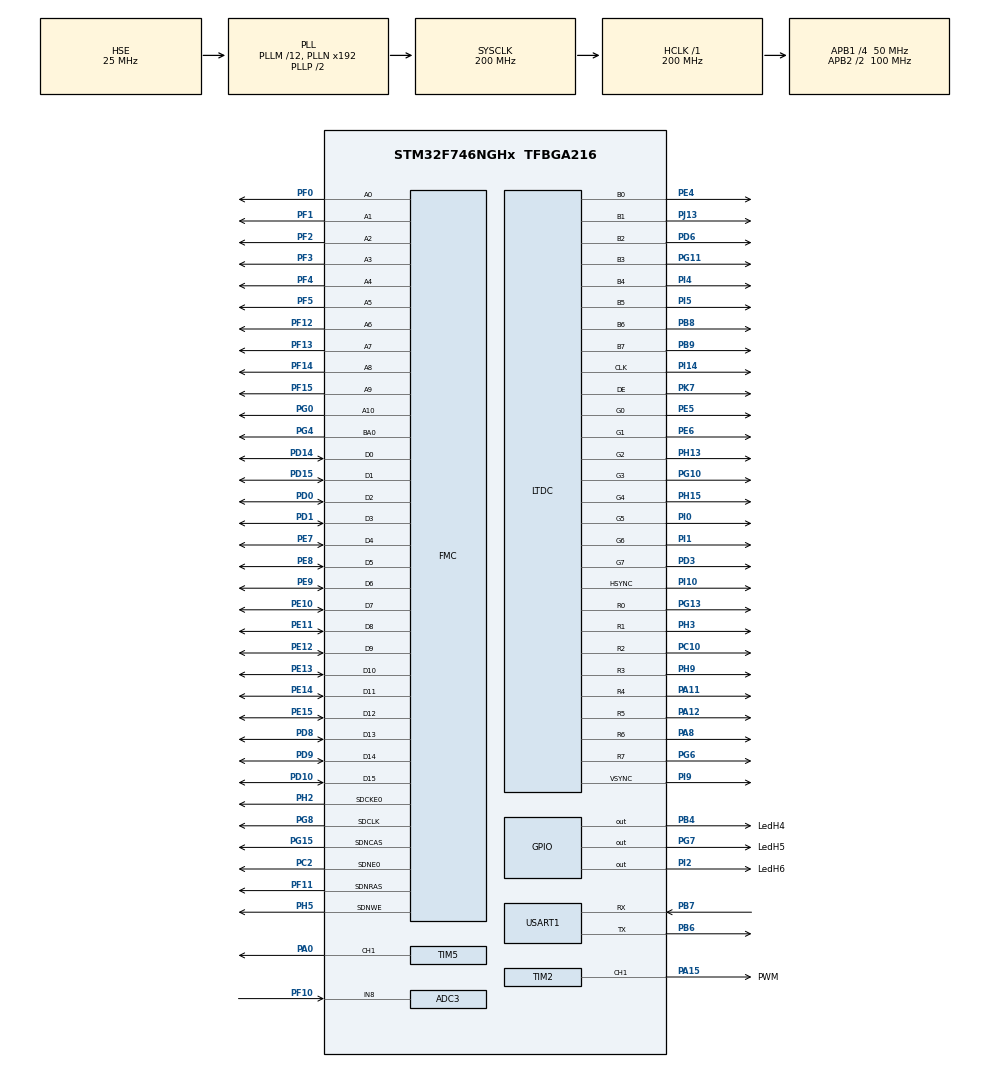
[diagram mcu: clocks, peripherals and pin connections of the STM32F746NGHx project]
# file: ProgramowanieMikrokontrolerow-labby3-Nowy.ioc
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ADC3.Channel-0\#ChannelRegularConversion=ADC_CHANNEL_8
ADC3.ContinuousConvMode=ENABLE
ADC3.NbrOfConversionFlag=1
ADC3.Rank-0\#ChannelRegularConversion=1
ADC3.SamplingTime-0\#ChannelRegularConversion=ADC_SAMPLETIME_3CYCLES
Dma.ADC3.0.Direction=DMA_PERIPH_TO_MEMORY
Dma.ADC3.0.FIFOMode=DMA_FIFOMODE_DISABLE
Dma.ADC3.0.Instance=DMA2_Stream0
Dma.ADC3.0.MemDataAlignment=DMA_MDATAALIGN_HALFWORD
Dma.ADC3.0.MemInc=DMA_MINC_ENABLE
Dma.ADC3.0.Mode=DMA_CIRCULAR
Dma.ADC3.0.PeriphDataAlignment=DMA_PDATAALIGN_HALFWORD
Dma.ADC3.0.PeriphInc=DMA_PINC_DISABLE
Dma.ADC3.0.Priority=DMA_PRIORITY_LOW
Dma.Request0=ADC3
Mcu.Family=STM32F7
Mcu.Name=STM32F746NGHx
Mcu.Package=TFBGA216
NVIC.ADC_IRQn=true\:0\:0\:false\:false\:true\:true\:true\:true
NVIC.DMA2_Stream0_IRQn=true\:0\:0\:false\:false\:true\:false\:true\:true
NVIC.PriorityGroup=NVIC_PRIORITYGROUP_4
NVIC.TIM2_IRQn=true\:0\:0\:false\:false\:true\:true\:true\:true
NVIC.TIM5_IRQn=true\:0\:0\:false\:false\:true\:true\:true\:true
PA0/WKUP.Signal=S_TIM5_CH1
PA11.Mode=RGB888
PA11.Signal=LTDC_R4
PA12.Mode=RGB888
PA12.Signal=LTDC_R5
PA15.GPIO_Label=PWM
PA15.Signal=S_TIM2_CH1_ETR
PA8.Mode=RGB888
PA8.Signal=LTDC_R6
PB4.GPIO_Label=LedH4
PB4.GPIO_PuPd=GPIO_PULLDOWN
PB4.Signal=GPIO_Output
PB6.Mode=Asynchronous
PB6.Signal=USART1_TX
PB7.Mode=Asynchronous
PB7.Signal=USART1_RX
PB8.Mode=RGB888
PB8.Signal=LTDC_B6
PB9.Mode=RGB888
PB9.Signal=LTDC_B7
PC10.Mode=RGB888
PC10.Signal=LTDC_R2
PC14/OSC32_IN.Mode=LSE-External-Oscillator
PC14/OSC32_IN.Signal=RCC_OSC32_IN
PC15/OSC32_OUT.Mode=LSE-External-Oscillator
PC15/OSC32_OUT.Signal=RCC_OSC32_OUT
PC2.Mode=SdramChipSelect1_1
PC2.Signal=FMC_SDNE0
PD0.Signal=FMC_D2_DA2
PD1.Signal=FMC_D3_DA3
PD10.Signal=FMC_D15_DA15
PD14.Signal=FMC_D0_DA0
PD15.Signal=FMC_D1_DA1
PD3.Mode=RGB888
PD3.Signal=LTDC_G7
PD6.Mode=RGB888
PD6.Signal=LTDC_B2
PD8.Signal=FMC_D13_DA13
PD9.Signal=FMC_D14_DA14
PE10.Signal=FMC_D7_DA7
PE11.Signal=FMC_D8_DA8
PE12.Signal=FMC_D9_DA9
PE13.Signal=FMC_D10_DA10
PE14.Signal=FMC_D11_DA11
PE15.Signal=FMC_D12_DA12
PE4.Mode=RGB888
PE4.Signal=LTDC_B0
PE5.Mode=RGB888
PE5.Signal=LTDC_G0
PE6.Mode=RGB888
PE6.Signal=LTDC_G1
PE7.Signal=FMC_D4_DA4
PE8.Signal=FMC_D5_DA5
PE9.Signal=FMC_D6_DA6
PF0.Signal=FMC_A0
PF1.Signal=FMC_A1
PF10.Mode=IN8
PF10.Signal=ADC3_IN8
PF11.Signal=FMC_SDNRAS
PF12.Signal=FMC_A6
PF13.Signal=FMC_A7
PF14.Signal=FMC_A8
PF15.Signal=FMC_A9
PF2.Signal=FMC_A2
PF3.Signal=FMC_A3
PF4.Signal=FMC_A4
PF5.Signal=FMC_A5
PG0.Signal=FMC_A10
PG10.Mode=RGB888
PG10.Signal=LTDC_G3
PG11.Mode=RGB888
PG11.Signal=LTDC_B3
PG13.Mode=RGB888
PG13.Signal=LTDC_R0
PG15.Signal=FMC_SDNCAS
PG4.Signal=FMC_A14_BA0
PG6.Mode=RGB888
PG6.Signal=LTDC_R7
PG7.GPIO_Label=LedH5
PG7.GPIO_PuPd=GPIO_PULLDOWN
PG7.Signal=GPIO_Output
PG8.Signal=FMC_SDCLK
PH0/OSC_IN.Mode=HSE-External-Oscillator
PH0/OSC_IN.Signal=RCC_OSC_IN
PH1/OSC_OUT.Mode=HSE-External-Oscillator
PH1/OSC_OUT.Signal=RCC_OSC_OUT
PH13.Mode=RGB888
PH13.Signal=LTDC_G2
PH15.Mode=RGB888
PH15.Signal=LTDC_G4
PH2.Mode=SdramChipSelect1_1
PH2.Signal=FMC_SDCKE0
PH3.Mode=RGB888
PH3.Signal=LTDC_R1
PH5.Signal=FMC_SDNWE
PH9.Mode=RGB888
PH9.Signal=LTDC_R3
PI0.Mode=RGB888
PI0.Signal=LTDC_G5
PI1.Mode=RGB888
PI1.Signal=LTDC_G6
PI10.Mode=RGB888
PI10.Signal=LTDC_HSYNC
PI14.Mode=RGB888
PI14.Signal=LTDC_CLK
PI2.GPIO_Label=LedH6
PI2.GPIO_PuPd=GPIO_PULLDOWN
PI2.Signal=GPIO_Output
PI4.Mode=RGB888
PI4.Signal=LTDC_B4
PI5.Mode=RGB888
PI5.Signal=LTDC_B5
PI9.Mode=RGB888
PI9.Signal=LTDC_VSYNC
PJ13.Mode=RGB888
PJ13.Signal=LTDC_B1
PK7.Mode=RGB888
PK7.Signal=LTDC_DE
ProjectManager.HeapSize=0x200
ProjectManager.StackSize=0x400
ProjectManager.TargetToolchain=STM32CubeIDE
RCC.AHBFreq_Value=200000000
RCC.APB1CLKDivider=RCC_HCLK_DIV4
RCC.APB1Freq_Value=50000000
RCC.APB1TimFreq_Value=100000000
RCC.APB2CLKDivider=RCC_HCLK_DIV2
RCC.APB2Freq_Value=100000000
RCC.APB2TimFreq_Value=200000000
RCC.CortexFreq_Value=200000000
RCC.HCLKFreq_Value=200000000
RCC.HSE_VALUE=25000000
RCC.HSI_VALUE=16000000
RCC.PLLM=12
RCC.PLLSAIN=50
RCC.PLLSourceVirtual=RCC_PLLSOURCE_HSE
RCC.SYSCLKFreq_VALUE=200000000
RCC.SYSCLKSource=RCC_SYSCLKSOURCE_PLLCLK
RCC.USBFreq_Value=200000000
RCC.VCOOutputFreq_Value=400000000
SH.FMC_A0.0=FMC_A0,11b-sda1
SH.FMC_A1.0=FMC_A1,11b-sda1
SH.FMC_A10.0=FMC_A10,11b-sda1
SH.FMC_A14_BA0.0=FMC_BA0,TwoSdramBanks1
SH.FMC_A2.0=FMC_A2,11b-sda1
SH.FMC_A3.0=FMC_A3,11b-sda1
SH.FMC_A4.0=FMC_A4,11b-sda1
SH.FMC_A5.0=FMC_A5,11b-sda1
SH.FMC_A6.0=FMC_A6,11b-sda1
SH.FMC_A7.0=FMC_A7,11b-sda1
SH.FMC_A8.0=FMC_A8,11b-sda1
SH.FMC_A9.0=FMC_A9,11b-sda1
SH.FMC_D0_DA0.0=FMC_D0,sd-16b-d1
SH.FMC_D10_DA10.0=FMC_D10,sd-16b-d1
SH.FMC_D11_DA11.0=FMC_D11,sd-16b-d1
SH.FMC_D12_DA12.0=FMC_D12,sd-16b-d1
SH.FMC_D13_DA13.0=FMC_D13,sd-16b-d1
SH.FMC_D14_DA14.0=FMC_D14,sd-16b-d1
SH.FMC_D15_DA15.0=FMC_D15,sd-16b-d1
SH.FMC_D1_DA1.0=FMC_D1,sd-16b-d1
SH.FMC_D2_DA2.0=FMC_D2,sd-16b-d1
SH.FMC_D3_DA3.0=FMC_D3,sd-16b-d1
SH.FMC_D4_DA4.0=FMC_D4,sd-16b-d1
SH.FMC_D5_DA5.0=FMC_D5,sd-16b-d1
SH.FMC_D6_DA6.0=FMC_D6,sd-16b-d1
SH.FMC_D7_DA7.0=FMC_D7,sd-16b-d1
SH.FMC_D8_DA8.0=FMC_D8,sd-16b-d1
SH.FMC_D9_DA9.0=FMC_D9,sd-16b-d1
SH.FMC_SDCLK.0=FMC_SDCLK,11b-sda1
SH.FMC_SDNCAS.0=FMC_SDNCAS,11b-sda1
SH.FMC_SDNRAS.0=FMC_SDNRAS,11b-sda1
SH.FMC_SDNWE.0=FMC_SDNWE,11b-sda1
SH.S_TIM2_CH1_ETR.0=TIM2_CH1,PWM Generation1 CH1
SH.S_TIM5_CH1.0=TIM5_CH1,PWM Generation1 CH1
TIM2.AutoReloadPreload=TIM_AUTORELOAD_PRELOAD_ENABLE
TIM2.Channel-PWM\ Generation1\ CH1=TIM_CHANNEL_1
TIM2.CounterMode=TIM_COUNTERMODE_CENTERALIGNED1
TIM2.OC1Preload_PWM=DISABLE
TIM2.Period=1999
TIM2.Pulse-PWM\ Generation1\ CH1=1000
TIM5.AutoReloadPreload=TIM_AUTORELOAD_PRELOAD_ENABLE
TIM5.Channel-PWM\ Generation1\ CH1=TIM_CHANNEL_1
TIM5.CounterMode=TIM_COUNTERMODE_CENTERALIGNED1
TIM5.Period=1999
USART1.VirtualMode-Asynchronous=VM_ASYNC
VP_CRC_VS_CRC.Mode=CRC_Activate
VP_DMA2D_VS_DMA2D.Mode=DMA2D_Activate
VP_TIM2_VS_ClockSourceINT.Mode=Internal
VP_TIM5_VS_ClockSourceINT.Mode=Internal
board=custom

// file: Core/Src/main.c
/* USER CODE BEGIN Header */
/**
  ******************************************************************************
  * @file           : main.c
  * @brief          : Main program body
  ******************************************************************************
  * @attention
  *
  * Copyright (c) 2024 STMicroelectronics.
  * All rights reserved.
  *
  * This software is licensed under terms that can be found in the LICENSE file
  * in the root directory of this software component.
  * If no LICENSE file comes with this software, it is provided AS-IS.
  *
  ******************************************************************************
  */
/* USER CODE END Header */
#include "main.h"

/* USER CODE BEGIN Includes */
#include "stm32746g_discovery.h"
#include "stm32746g_discovery_sdram.h"
#include "stm32746g_discovery_ts.h"
#include "stm32746g_discovery_lcd.h"
#include "stdio.h"
#include "math.h"
/* USER CODE END Includes */

/* USER CODE BEGIN PD */
// Definicje przycisków i pozycji tekstu
#define SHIFT 55

#define BUTTON_WIDTH (100 + SHIFT)
#define BUTTON_HEIGHT 50
#define BUTTON_SPACING 10

#define BUTTON_ON_OFF_X 20
#define BUTTON_ON_OFF_Y 20

#define BUTTON_MODE_X 20
#define BUTTON_MODE_Y (BUTTON_ON_OFF_Y + BUTTON_HEIGHT + BUTTON_SPACING)

#define BUTTON_AMPLITUDE_UP_X 20
#define BUTTON_AMPLITUDE_UP_Y (BUTTON_MODE_Y + BUTTON_HEIGHT + BUTTON_SPACING)

#define BUTTON_AMPLITUDE_DOWN_X 20
#define BUTTON_AMPLITUDE_DOWN_Y (BUTTON_AMPLITUDE_UP_Y + BUTTON_HEIGHT + BUTTON_SPACING)

#define TEXT_OFFSET_X (140 + SHIFT)
#define TEXT_OFFSET_Y 20
#define TEXT_SPACING 30

/* USER CODE END PD */

ADC_HandleTypeDef hadc3;
DMA_HandleTypeDef hdma_adc3;

CRC_HandleTypeDef hcrc;

DMA2D_HandleTypeDef hdma2d;

LTDC_HandleTypeDef hltdc;

TIM_HandleTypeDef htim2;
TIM_HandleTypeDef htim5;

UART_HandleTypeDef huart1;

SDRAM_HandleTypeDef hsdram1;

/* USER CODE BEGIN PV */
uint16_t tikTak1 = 1, tikTak2 = 1, tikTak3 = 1, tikTak4 = 1;

int16_t dmaBuffor[4];
float adcAvg = 0;

TS_StateTypeDef ts;
char xTouchStr[10];

uint8_t stan = 0;

uint16_t tim2IntTimes = 0;
float SinPeriodOffset = 6.28 / 2500;
uint32_t sinTable[200];

TS_StateTypeDef TS_State;
char xTouchStr[10];

uint8_t signal_on = 0;
uint8_t generation_mode = 1;
uint8_t fundamental_amplitude = 50;
uint8_t harmonic_amplitude = 50;

uint8_t harmonic = 3;

/* USER CODE END PV */

void SystemClock_Config(void);
static void MX_GPIO_Init(void);
static void MX_DMA_Init(void);
static void MX_DMA2D_Init(void);
static void MX_FMC_Init(void);
static void MX_LTDC_Init(void);
static void MX_TIM2_Init(void);
static void MX_USART1_UART_Init(void);
static void MX_ADC3_Init(void);
static void MX_CRC_Init(void);
static void MX_TIM5_Init(void);
/* USER CODE BEGIN PFP */
static void CreateSinTable(void);
void ProcessTouch(uint16_t x, uint16_t y);
void UpdateDisplay();
void DrawButtons(void);
void InitDisplay();

/* USER CODE END PFP */

int main(void)
{

  /* MCU Configuration--------------------------------------------------------*/

  /* Reset of all peripherals, Initializes the Flash interface and the Systick. */
  HAL_Init();

  /* Configure the system clock */
  SystemClock_Config();

  /* Initialize all configured peripherals */
  MX_GPIO_Init();
  MX_DMA_Init();
  MX_DMA2D_Init();
  MX_FMC_Init();
  MX_LTDC_Init();
  MX_TIM2_Init();
  MX_USART1_UART_Init();
  MX_ADC3_Init();
  MX_CRC_Init();
  MX_TIM5_Init();
  /* USER CODE BEGIN 2 */
  CreateSinTable();
  //HAL_TIM_PWM_Start_IT(&htim2, TIM_CHANNEL_1);
  //HAL_TIM_PWM_Start_IT(&htim5, TIM_CHANNEL_1);
  //HAL_ADC_Start_DMA(&hadc3, dmaBuffor, 4);

  /* USER CODE END 2 */

  /* Infinite loop */
  /* USER CODE BEGIN WHILE */
  InitDisplay();
  while (1)
    {
    /* USER CODE END WHILE */

    /* USER CODE BEGIN 3 */

  	  if((uwTick % 2U) == 0U) //co 1ms
  	  	  {
  	  	 	  tikTak1++;
  	  	 	  tikTak2++;
  	  	 	  tikTak3++;
  	  	 	  tikTak4++;
  	  	 	  uwTick = 1;

  	  	 	  HAL_ADC_Start_IT(&hadc3);
  	  	 	  //////// SREDNIA DO ZADANA 9 /////////
  	  	 	  //adcAvg = 0;
  	  	 	  float tmpAvg = 0;
  	  	 	  for(int i=0; i<4; i++) {
  	  	 		 float tmp = dmaBuffor[i];
  	  	 		 tmpAvg += tmp / 4095.0;
  	  	 	  }
  	  	 	 tmpAvg /= 4U;
  	  	 	 adcAvg = tmpAvg;

  	  	 	 if (adcAvg < 0.05) {
  	  	 		 adcAvg = 0.05;
  	  	 	 } else if (adcAvg > 0.9) {
  	  	 		 adcAvg = 0.9;
  	  	 	 }

  	  	 	 harmonic_amplitude = adcAvg * 100;
  	  	 	  ////////////////KONIEC SREDNIA //////////
  	  	  }

  	  	  if((tikTak1 % 11) == 0) //co 10ms sie zmienia
  	  	  {
  	  		  //HAL_GPIO_TogglePin(GPIOB, LedH4_Pin);
  	  		  tikTak1 = 1;
  	  		  //HAL_ADC_Start_DMA(&hadc3, dmaBuffor, 4);
  	  	  }
  	  	  if((tikTak2 % 101U) == 0) // co 100ms
  	      {
  	  		  HAL_GPIO_TogglePin(GPIOG, LedH5_Pin);
  	  		  tikTak2 = 1;

  	  		  BSP_TS_GetState(&TS_State);
  	  		  if (TS_State.touchDetected) { //tutaj dodać lub po zmianie wartości odczytanej z potencjometru
  	  			  ProcessTouch(TS_State.touchX[0], TS_State.touchY[0]);
  	  		  }
  	  		  UpdateDisplay();
  	  	  }
  	  	  if((tikTak3 % 1001U) == 0U) //co 1000ms (1s)
  	  	  {
  	  	  	  HAL_GPIO_TogglePin(LedH6_GPIO_Port, LedH6_Pin);
  	  	  	  tikTak3 = 1;
  	  	  }
  	  	  if((tikTak4 % 10001U) == 0U) //co 10 000ms
  	  	  {
  	  	   	  tikTak4 = 1;
  	  	  }

  	    }
  /* USER CODE END 3 */
}

void SystemClock_Config(void)
{
  RCC_OscInitTypeDef RCC_OscInitStruct = {0};
  RCC_ClkInitTypeDef RCC_ClkInitStruct = {0};

  /** Configure LSE Drive Capability
  */
  HAL_PWR_EnableBkUpAccess();

  /** Configure the main internal regulator output voltage
  */
  __HAL_RCC_PWR_CLK_ENABLE();
  __HAL_PWR_VOLTAGESCALING_CONFIG(PWR_REGULATOR_VOLTAGE_SCALE1);

  /** Initializes the RCC Oscillators according to the specified parameters
  * in the RCC_OscInitTypeDef structure.
  */
  RCC_OscInitStruct.OscillatorType = RCC_OSCILLATORTYPE_HSE;
  RCC_OscInitStruct.HSEState = RCC_HSE_ON;
  RCC_OscInitStruct.PLL.PLLState = RCC_PLL_ON;
  RCC_OscInitStruct.PLL.PLLSource = RCC_PLLSOURCE_HSE;
  RCC_OscInitStruct.PLL.PLLM = 12;
  RCC_OscInitStruct.PLL.PLLN = 192;
  RCC_OscInitStruct.PLL.PLLP = RCC_PLLP_DIV2;
  RCC_OscInitStruct.PLL.PLLQ = 2;
  if (HAL_RCC_OscConfig(&RCC_OscInitStruct) != HAL_OK)
  {
    Error_Handler();
  }

  /** Activate the Over-Drive mode
  */
  if (HAL_PWREx_EnableOverDrive() != HAL_OK)
  {
    Error_Handler();
  }

  /** Initializes the CPU, AHB and APB buses clocks
  */
  RCC_ClkInitStruct.ClockType = RCC_CLOCKTYPE_HCLK|RCC_CLOCKTYPE_SYSCLK
                              |RCC_CLOCKTYPE_PCLK1|RCC_CLOCKTYPE_PCLK2;
  RCC_ClkInitStruct.SYSCLKSource = RCC_SYSCLKSOURCE_PLLCLK;
  RCC_ClkInitStruct.AHBCLKDivider = RCC_SYSCLK_DIV1;
  RCC_ClkInitStruct.APB1CLKDivider = RCC_HCLK_DIV4;
  RCC_ClkInitStruct.APB2CLKDivider = RCC_HCLK_DIV2;

  if (HAL_RCC_ClockConfig(&RCC_ClkInitStruct, FLASH_LATENCY_6) != HAL_OK)
  {
    Error_Handler();
  }
}

static void MX_ADC3_Init(void)
{

  ADC_ChannelConfTypeDef sConfig = {0};

  /** Configure the global features of the ADC (Clock, Resolution, Data Alignment and number of conversion)
  */
  hadc3.Instance = ADC3;
  hadc3.Init.ClockPrescaler = ADC_CLOCK_SYNC_PCLK_DIV4;
  hadc3.Init.Resolution = ADC_RESOLUTION_12B;
  hadc3.Init.ScanConvMode = ADC_SCAN_DISABLE;
  hadc3.Init.ContinuousConvMode = ENABLE;
  hadc3.Init.DiscontinuousConvMode = DISABLE;
  hadc3.Init.ExternalTrigConvEdge = ADC_EXTERNALTRIGCONVEDGE_NONE;
  hadc3.Init.ExternalTrigConv = ADC_SOFTWARE_START;
  hadc3.Init.DataAlign = ADC_DATAALIGN_RIGHT;
  hadc3.Init.NbrOfConversion = 1;
  hadc3.Init.DMAContinuousRequests = DISABLE;
  hadc3.Init.EOCSelection = ADC_EOC_SINGLE_CONV;
  if (HAL_ADC_Init(&hadc3) != HAL_OK)
  {
    Error_Handler();
  }

  /** Configure for the selected ADC regular channel its corresponding rank in the sequencer and its sample time.
  */
  sConfig.Channel = ADC_CHANNEL_8;
  sConfig.Rank = ADC_REGULAR_RANK_1;
  sConfig.SamplingTime = ADC_SAMPLETIME_3CYCLES;
  if (HAL_ADC_ConfigChannel(&hadc3, &sConfig) != HAL_OK)
  {
    Error_Handler();
  }

}

static void MX_CRC_Init(void)
{

  hcrc.Instance = CRC;
  hcrc.Init.DefaultPolynomialUse = DEFAULT_POLYNOMIAL_ENABLE;
  hcrc.Init.DefaultInitValueUse = DEFAULT_INIT_VALUE_ENABLE;
  hcrc.Init.InputDataInversionMode = CRC_INPUTDATA_INVERSION_NONE;
  hcrc.Init.OutputDataInversionMode = CRC_OUTPUTDATA_INVERSION_DISABLE;
  hcrc.InputDataFormat = CRC_INPUTDATA_FORMAT_BYTES;
  if (HAL_CRC_Init(&hcrc) != HAL_OK)
  {
    Error_Handler();
  }

}

static void MX_DMA2D_Init(void)
{

  hdma2d.Instance = DMA2D;
  hdma2d.Init.Mode = DMA2D_M2M;
  hdma2d.Init.ColorMode = DMA2D_OUTPUT_ARGB8888;
  hdma2d.Init.OutputOffset = 0;
  hdma2d.LayerCfg[1].InputOffset = 0;
  hdma2d.LayerCfg[1].InputColorMode = DMA2D_INPUT_ARGB8888;
  hdma2d.LayerCfg[1].AlphaMode = DMA2D_NO_MODIF_ALPHA;
  hdma2d.LayerCfg[1].InputAlpha = 0;
  if (HAL_DMA2D_Init(&hdma2d) != HAL_OK)
  {
    Error_Handler();
  }
  if (HAL_DMA2D_ConfigLayer(&hdma2d, 1) != HAL_OK)
  {
    Error_Handler();
  }

}

static void MX_LTDC_Init(void)
{

  LTDC_LayerCfgTypeDef pLayerCfg = {0};
  LTDC_LayerCfgTypeDef pLayerCfg1 = {0};

  hltdc.Instance = LTDC;
  hltdc.Init.HSPolarity = LTDC_HSPOLARITY_AL;
  hltdc.Init.VSPolarity = LTDC_VSPOLARITY_AL;
  hltdc.Init.DEPolarity = LTDC_DEPOLARITY_AL;
  hltdc.Init.PCPolarity = LTDC_PCPOLARITY_IPC;
  hltdc.Init.HorizontalSync = 7;
  hltdc.Init.VerticalSync = 3;
  hltdc.Init.AccumulatedHBP = 14;
  hltdc.Init.AccumulatedVBP = 5;
  hltdc.Init.AccumulatedActiveW = 654;
  hltdc.Init.AccumulatedActiveH = 485;
  hltdc.Init.TotalWidth = 660;
  hltdc.Init.TotalHeigh = 487;
  hltdc.Init.Backcolor.Blue = 0;
  hltdc.Init.Backcolor.Green = 0;
  hltdc.Init.Backcolor.Red = 0;
  if (HAL_LTDC_Init(&hltdc) != HAL_OK)
  {
    Error_Handler();
  }
  pLayerCfg.WindowX0 = 0;
  pLayerCfg.WindowX1 = 0;
  pLayerCfg.WindowY0 = 0;
  pLayerCfg.WindowY1 = 0;
  pLayerCfg.PixelFormat = LTDC_PIXEL_FORMAT_ARGB8888;
  pLayerCfg.Alpha = 0;
  pLayerCfg.Alpha0 = 0;
  pLayerCfg.BlendingFactor1 = LTDC_BLENDING_FACTOR1_CA;
  pLayerCfg.BlendingFactor2 = LTDC_BLENDING_FACTOR2_CA;
  pLayerCfg.FBStartAdress = 0;
  pLayerCfg.ImageWidth = 0;
  pLayerCfg.ImageHeight = 0;
  pLayerCfg.Backcolor.Blue = 0;
  pLayerCfg.Backcolor.Green = 0;
  pLayerCfg.Backcolor.Red = 0;
  if (HAL_LTDC_ConfigLayer(&hltdc, &pLayerCfg, 0) != HAL_OK)
  {
    Error_Handler();
  }
  pLayerCfg1.WindowX0 = 0;
  pLayerCfg1.WindowX1 = 0;
  pLayerCfg1.WindowY0 = 0;
  pLayerCfg1.WindowY1 = 0;
  pLayerCfg1.PixelFormat = LTDC_PIXEL_FORMAT_ARGB8888;
  pLayerCfg1.Alpha = 0;
  pLayerCfg1.Alpha0 = 0;
  pLayerCfg1.BlendingFactor1 = LTDC_BLENDING_FACTOR1_CA;
  pLayerCfg1.BlendingFactor2 = LTDC_BLENDING_FACTOR2_CA;
  pLayerCfg1.FBStartAdress = 0;
  pLayerCfg1.ImageWidth = 0;
  pLayerCfg1.ImageHeight = 0;
  pLayerCfg1.Backcolor.Blue = 0;
  pLayerCfg1.Backcolor.Green = 0;
  pLayerCfg1.Backcolor.Red = 0;
  if (HAL_LTDC_ConfigLayer(&hltdc, &pLayerCfg1, 1) != HAL_OK)
  {
    Error_Handler();
  }

}

static void MX_TIM2_Init(void)
{

  TIM_ClockConfigTypeDef sClockSourceConfig = {0};
  TIM_MasterConfigTypeDef sMasterConfig = {0};
  TIM_OC_InitTypeDef sConfigOC = {0};

  htim2.Instance = TIM2;
  htim2.Init.Prescaler = 0;
  htim2.Init.CounterMode = TIM_COUNTERMODE_CENTERALIGNED1;
  htim2.Init.Period = 1999;
  htim2.Init.ClockDivision = TIM_CLOCKDIVISION_DIV1;
  htim2.Init.AutoReloadPreload = TIM_AUTORELOAD_PRELOAD_ENABLE;
  if (HAL_TIM_Base_Init(&htim2) != HAL_OK)
  {
    Error_Handler();
  }
  sClockSourceConfig.ClockSource = TIM_CLOCKSOURCE_INTERNAL;
  if (HAL_TIM_ConfigClockSource(&htim2, &sClockSourceConfig) != HAL_OK)
  {
    Error_Handler();
  }
  if (HAL_TIM_PWM_Init(&htim2) != HAL_OK)
  {
    Error_Handler();
  }
  sMasterConfig.MasterOutputTrigger = TIM_TRGO_RESET;
  sMasterConfig.MasterSlaveMode = TIM_MASTERSLAVEMODE_DISABLE;
  if (HAL_TIMEx_MasterConfigSynchronization(&htim2, &sMasterConfig) != HAL_OK)
  {
    Error_Handler();
  }
  sConfigOC.OCMode = TIM_OCMODE_PWM1;
  sConfigOC.Pulse = 1000;
  sConfigOC.OCPolarity = TIM_OCPOLARITY_HIGH;
  sConfigOC.OCFastMode = TIM_OCFAST_DISABLE;
  if (HAL_TIM_PWM_ConfigChannel(&htim2, &sConfigOC, TIM_CHANNEL_1) != HAL_OK)
  {
    Error_Handler();
  }
  __HAL_TIM_DISABLE_OCxPRELOAD(&htim2, TIM_CHANNEL_1);
  HAL_TIM_MspPostInit(&htim2);

}

static void MX_TIM5_Init(void)
{

  TIM_ClockConfigTypeDef sClockSourceConfig = {0};
  TIM_MasterConfigTypeDef sMasterConfig = {0};
  TIM_OC_InitTypeDef sConfigOC = {0};

  htim5.Instance = TIM5;
  htim5.Init.Prescaler = 0;
  htim5.Init.CounterMode = TIM_COUNTERMODE_CENTERALIGNED1;
  htim5.Init.Period = 1999;
  htim5.Init.ClockDivision = TIM_CLOCKDIVISION_DIV1;
  htim5.Init.AutoReloadPreload = TIM_AUTORELOAD_PRELOAD_ENABLE;
  if (HAL_TIM_Base_Init(&htim5) != HAL_OK)
  {
    Error_Handler();
  }
  sClockSourceConfig.ClockSource = TIM_CLOCKSOURCE_INTERNAL;
  if (HAL_TIM_ConfigClockSource(&htim5, &sClockSourceConfig) != HAL_OK)
  {
    Error_Handler();
  }
  if (HAL_TIM_PWM_Init(&htim5) != HAL_OK)
  {
    Error_Handler();
  }
  sMasterConfig.MasterOutputTrigger = TIM_TRGO_RESET;
  sMasterConfig.MasterSlaveMode = TIM_MASTERSLAVEMODE_DISABLE;
  if (HAL_TIMEx_MasterConfigSynchronization(&htim5, &sMasterConfig) != HAL_OK)
  {
    Error_Handler();
  }
  sConfigOC.OCMode = TIM_OCMODE_PWM1;
  sConfigOC.Pulse = 900;
  sConfigOC.OCPolarity = TIM_OCPOLARITY_HIGH;
  sConfigOC.OCFastMode = TIM_OCFAST_DISABLE;
  if (HAL_TIM_PWM_ConfigChannel(&htim5, &sConfigOC, TIM_CHANNEL_1) != HAL_OK)
  {
    Error_Handler();
  }
  HAL_TIM_MspPostInit(&htim5);

}

static void MX_USART1_UART_Init(void)
{

  huart1.Instance = USART1;
  huart1.Init.BaudRate = 115200;
  huart1.Init.WordLength = UART_WORDLENGTH_8B;
  huart1.Init.StopBits = UART_STOPBITS_1;
  huart1.Init.Parity = UART_PARITY_NONE;
  huart1.Init.Mode = UART_MODE_TX_RX;
  huart1.Init.HwFlowCtl = UART_HWCONTROL_NONE;
  huart1.Init.OverSampling = UART_OVERSAMPLING_16;
  huart1.Init.OneBitSampling = UART_ONE_BIT_SAMPLE_DISABLE;
  huart1.AdvancedInit.AdvFeatureInit = UART_ADVFEATURE_NO_INIT;
  if (HAL_UART_Init(&huart1) != HAL_OK)
  {
    Error_Handler();
  }

}

static void MX_DMA_Init(void)
{

  /* DMA controller clock enable */
  __HAL_RCC_DMA2_CLK_ENABLE();

  /* DMA interrupt init */
  /* DMA2_Stream0_IRQn interrupt configuration */
  HAL_NVIC_SetPriority(DMA2_Stream0_IRQn, 0, 0);
  HAL_NVIC_EnableIRQ(DMA2_Stream0_IRQn);

}

/* FMC initialization function */
static void MX_FMC_Init(void)
{

  FMC_SDRAM_TimingTypeDef SdramTiming = {0};

  /** Perform the SDRAM1 memory initialization sequence
  */
  hsdram1.Instance = FMC_SDRAM_DEVICE;
  /* hsdram1.Init */
  hsdram1.Init.SDBank = FMC_SDRAM_BANK1;
  hsdram1.Init.ColumnBitsNumber = FMC_SDRAM_COLUMN_BITS_NUM_8;
  hsdram1.Init.RowBitsNumber = FMC_SDRAM_ROW_BITS_NUM_11;
  hsdram1.Init.MemoryDataWidth = FMC_SDRAM_MEM_BUS_WIDTH_16;
  hsdram1.Init.InternalBankNumber = FMC_SDRAM_INTERN_BANKS_NUM_2;
  hsdram1.Init.CASLatency = FMC_SDRAM_CAS_LATENCY_1;
  hsdram1.Init.WriteProtection = FMC_SDRAM_WRITE_PROTECTION_DISABLE;
  hsdram1.Init.SDClockPeriod = FMC_SDRAM_CLOCK_DISABLE;
  hsdram1.Init.ReadBurst = FMC_SDRAM_RBURST_DISABLE;
  hsdram1.Init.ReadPipeDelay = FMC_SDRAM_RPIPE_DELAY_0;
  /* SdramTiming */
  SdramTiming.LoadToActiveDelay = 16;
  SdramTiming.ExitSelfRefreshDelay = 16;
  SdramTiming.SelfRefreshTime = 16;
  SdramTiming.RowCycleDelay = 16;
  SdramTiming.WriteRecoveryTime = 16;
  SdramTiming.RPDelay = 16;
  SdramTiming.RCDDelay = 16;

  if (HAL_SDRAM_Init(&hsdram1, &SdramTiming) != HAL_OK)
  {
    Error_Handler( );
  }

}

static void MX_GPIO_Init(void)
{
  GPIO_InitTypeDef GPIO_InitStruct = {0};

  /* GPIO Ports Clock Enable */
  __HAL_RCC_GPIOE_CLK_ENABLE();
  __HAL_RCC_GPIOB_CLK_ENABLE();
  __HAL_RCC_GPIOA_CLK_ENABLE();
  __HAL_RCC_GPIOG_CLK_ENABLE();
  __HAL_RCC_GPIOJ_CLK_ENABLE();
  __HAL_RCC_GPIOD_CLK_ENABLE();
  __HAL_RCC_GPIOC_CLK_ENABLE();
  __HAL_RCC_GPIOI_CLK_ENABLE();
  __HAL_RCC_GPIOK_CLK_ENABLE();
  __HAL_RCC_GPIOF_CLK_ENABLE();
  __HAL_RCC_GPIOH_CLK_ENABLE();

  /*Configure GPIO pin Output Level */
  HAL_GPIO_WritePin(LedH4_GPIO_Port, LedH4_Pin, GPIO_PIN_RESET);

  /*Configure GPIO pin Output Level */
  HAL_GPIO_WritePin(LedH6_GPIO_Port, LedH6_Pin, GPIO_PIN_RESET);

  /*Configure GPIO pin Output Level */
  HAL_GPIO_WritePin(LedH5_GPIO_Port, LedH5_Pin, GPIO_PIN_RESET);

  /*Configure GPIO pin : LedH4_Pin */
  GPIO_InitStruct.Pin = LedH4_Pin;
  GPIO_InitStruct.Mode = GPIO_MODE_OUTPUT_PP;
  GPIO_InitStruct.Pull = GPIO_PULLDOWN;
  GPIO_InitStruct.Speed = GPIO_SPEED_FREQ_LOW;
  HAL_GPIO_Init(LedH4_GPIO_Port, &GPIO_InitStruct);

  /*Configure GPIO pin : LedH6_Pin */
  GPIO_InitStruct.Pin = LedH6_Pin;
  GPIO_InitStruct.Mode = GPIO_MODE_OUTPUT_PP;
  GPIO_InitStruct.Pull = GPIO_PULLDOWN;
  GPIO_InitStruct.Speed = GPIO_SPEED_FREQ_LOW;
  HAL_GPIO_Init(LedH6_GPIO_Port, &GPIO_InitStruct);

  /*Configure GPIO pin : LedH5_Pin */
  GPIO_InitStruct.Pin = LedH5_Pin;
  GPIO_InitStruct.Mode = GPIO_MODE_OUTPUT_PP;
  GPIO_InitStruct.Pull = GPIO_PULLDOWN;
  GPIO_InitStruct.Speed = GPIO_SPEED_FREQ_LOW;
  HAL_GPIO_Init(LedH5_GPIO_Port, &GPIO_InitStruct);

}

/* USER CODE BEGIN 4 */
static void CreateSinTable()
{
	float tmp = 6.28 / 200;
	int i = 0;
	for(i = 0; i < 200; i++)
	{
		sinTable[i] = 990 * (sin(tmp * i) + 1);

		if(sinTable[i] > PWM_MAX_VALUE) { sinTable[i] = PWM_MAX_VALUE; }
		else if (sinTable[i] < PWM_MIN_VALUE) { sinTable[i] = PWM_MIN_VALUE; }
	}
}

void InitDisplay() {
    // Inicjalizacja LCD
    BSP_LCD_Init();
    BSP_LCD_LayerDefaultInit(0, LCD_FB_START_ADDRESS);
    BSP_LCD_SelectLayer(0);
    BSP_LCD_Clear(LCD_COLOR_WHITE);
    BSP_LCD_SetBackColor(LCD_COLOR_WHITE);
    BSP_LCD_SetTextColor(LCD_COLOR_BLACK);
    BSP_LCD_SetFont(&Font24);

    // Inicjalizacja ekranu dotykowego
    BSP_TS_Init(BSP_LCD_GetXSize(), BSP_LCD_GetYSize());

    // Rysowanie przycisków
    DrawButtons();

    // Aktualizacja wyświetlanych wartości
    UpdateDisplay();
}

void DrawButtons(void) {
    // Rysowanie przycisku On/Off
    BSP_LCD_SetTextColor(LCD_COLOR_GREEN);
    BSP_LCD_FillRect(BUTTON_ON_OFF_X, BUTTON_ON_OFF_Y, BUTTON_WIDTH, BUTTON_HEIGHT);
    BSP_LCD_SetTextColor(LCD_COLOR_BLACK);
    BSP_LCD_DisplayStringAt(BUTTON_ON_OFF_X + 10, BUTTON_ON_OFF_Y + 15, (uint8_t *)"On/Off", LEFT_MODE);

    // Rysowanie przycisku Tryb
    BSP_LCD_SetTextColor(LCD_COLOR_BLUE);
    BSP_LCD_FillRect(BUTTON_MODE_X, BUTTON_MODE_Y, BUTTON_WIDTH, BUTTON_HEIGHT);
    BSP_LCD_SetTextColor(LCD_COLOR_BLACK);
    BSP_LCD_DisplayStringAt(BUTTON_MODE_X + 10, BUTTON_MODE_Y + 15, (uint8_t *)"Tryb", LEFT_MODE);

    // Rysowanie przycisku Amplituda Up
    BSP_LCD_SetTextColor(LCD_COLOR_RED);
    BSP_LCD_FillRect(BUTTON_AMPLITUDE_UP_X, BUTTON_AMPLITUDE_UP_Y, BUTTON_WIDTH, BUTTON_HEIGHT);
    BSP_LCD_SetTextColor(LCD_COLOR_BLACK);
    BSP_LCD_DisplayStringAt(BUTTON_AMPLITUDE_UP_X + 10, BUTTON_AMPLITUDE_UP_Y + 15, (uint8_t *)"Amp 1h +", LEFT_MODE);

    // Rysowanie przycisku Amplituda Down
    BSP_LCD_SetTextColor(LCD_COLOR_RED);
    BSP_LCD_FillRect(BUTTON_AMPLITUDE_DOWN_X, BUTTON_AMPLITUDE_DOWN_Y, BUTTON_WIDTH, BUTTON_HEIGHT);
    BSP_LCD_SetTextColor(LCD_COLOR_BLACK);
    BSP_LCD_DisplayStringAt(BUTTON_AMPLITUDE_DOWN_X + 10, BUTTON_AMPLITUDE_DOWN_Y + 15, (uint8_t *)"Amp 1h -", LEFT_MODE);
}

void UpdateDisplay() {
    char buffer[30];

    // Wyświetlanie stanu sygnału
    sprintf(buffer, "Sygnal: %s", signal_on ? "On " : "Off");
    BSP_LCD_DisplayStringAt(TEXT_OFFSET_X, TEXT_OFFSET_Y, (uint8_t *)buffer, LEFT_MODE);

    // Wyświetlanie trybu generacji
    sprintf(buffer, "Tryb: %s", generation_mode ? "1+3h" : "1+5h");
    BSP_LCD_DisplayStringAt(TEXT_OFFSET_X, TEXT_OFFSET_Y + TEXT_SPACING, (uint8_t *)buffer, LEFT_MODE);

    // Wyświetlanie amplitudy podstawowej harmonicznej
    sprintf(buffer, "Amp. 1h: %.3d%%", fundamental_amplitude);
    BSP_LCD_DisplayStringAt(TEXT_OFFSET_X, TEXT_OFFSET_Y + 2 * TEXT_SPACING, (uint8_t *)buffer, LEFT_MODE);

    // Wyświetlanie amplitudy drugiej harmonicznej
    sprintf(buffer, "Amp. %s: %.3d%%", generation_mode ? "3h" : "5h", harmonic_amplitude);
    BSP_LCD_DisplayStringAt(TEXT_OFFSET_X, TEXT_OFFSET_Y + 3 * TEXT_SPACING, (uint8_t *)buffer, LEFT_MODE);
}

void ProcessTouch(uint16_t x, uint16_t y) {
    if (x > BUTTON_ON_OFF_X && x < BUTTON_ON_OFF_X + BUTTON_WIDTH &&
        y > BUTTON_ON_OFF_Y && y < BUTTON_ON_OFF_Y + BUTTON_HEIGHT) {
        signal_on = !signal_on;
        if (signal_on == 1) {
        	HAL_GPIO_WritePin(GPIOB, LedH4_Pin, 1);

        	HAL_TIM_PWM_Start_IT(&htim5, TIM_CHANNEL_1);
        } else {
        	HAL_GPIO_WritePin(GPIOB, LedH4_Pin, 0);

        	HAL_TIM_PWM_Stop_IT(&htim5, TIM_CHANNEL_1);
        }
    } else if (x > BUTTON_MODE_X && x < BUTTON_MODE_X + BUTTON_WIDTH &&
               y > BUTTON_MODE_Y && y < BUTTON_MODE_Y + BUTTON_HEIGHT) {
        generation_mode = !generation_mode;
        if (generation_mode == 1) {
        	harmonic = 3;
        } else {
        	harmonic = 5;
        }
    } else if (x > BUTTON_AMPLITUDE_UP_X && x < BUTTON_AMPLITUDE_UP_X + BUTTON_WIDTH &&
               y > BUTTON_AMPLITUDE_UP_Y && y < BUTTON_AMPLITUDE_UP_Y + BUTTON_HEIGHT) {
        if (fundamental_amplitude < 100) {
            fundamental_amplitude += 10;
        }
    } else if (x > BUTTON_AMPLITUDE_DOWN_X && x < BUTTON_AMPLITUDE_DOWN_X + BUTTON_WIDTH &&
               y > BUTTON_AMPLITUDE_DOWN_Y && y < BUTTON_AMPLITUDE_DOWN_Y + BUTTON_HEIGHT) {
        if (fundamental_amplitude > 10) {
            fundamental_amplitude -= 10;
        }
    }
    // Aktualizacja wyświetlanych wartości
    UpdateDisplay();
}
/* USER CODE END 4 */

void Error_Handler(void)
{
  __disable_irq();
  while (1)
  {
  }
}
